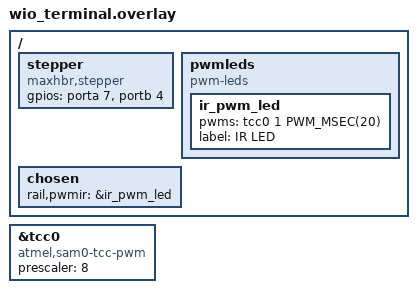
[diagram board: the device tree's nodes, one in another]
/*
 *
 * SPDX-License-Identifier: Apache-2.0
 */
#include <zephyr/dt-bindings/input/input-event-codes.h>
#include <zephyr/dt-bindings/lvgl/lvgl.h>
/ {
	stepper: stepper {
		compatible = "maxhbr,stepper";
		gpios = <&porta 7 GPIO_ACTIVE_HIGH>, /* A2/D2 */
		        <&portb 4 GPIO_ACTIVE_HIGH>;    /* A3/D3 */
		//pitch = <2>;
		//pulses_per_rev = <50000>;
	};

//  lvgl_keypad_input {
//          compatible = "zephyr,lvgl-keypad-input";
//          input-codes = <INPUT_KEY_LEFT INPUT_KEY_RIGHT INPUT_KEY_ENTER>;
//          lvgl-codes = <LV_KEY_LEFT LV_KEY_RIGHT LV_KEY_ENTER>;
//  };

//  lvgl_up_down_input {
//          compatible = "zephyr,lvgl-keypad-input";
//          input-codes = <INPUT_KEY_UP INPUT_KEY_DOWN>;
//          lvgl-codes = <LV_KEY_UP LV_KEY_DOWN>;
//  };

	pwmleds {
		compatible = "pwm-leds";
		ir_pwm_led: ir_pwm_led {
			pwms = <&tcc0 1 PWM_MSEC(20)>;
			label = "IR LED";
		};
	};

	chosen {
		rail,pwmir = &ir_pwm_led;
	};


};
&tcc0 {
	compatible = "atmel,sam0-tcc-pwm";
	prescaler = <8>;
	#pwm-cells = <2>;
};
